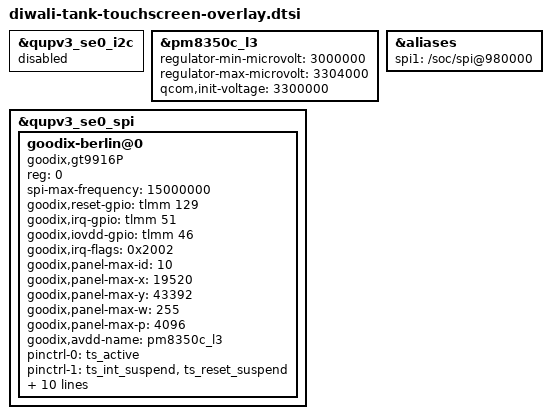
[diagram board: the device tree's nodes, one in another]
/*
 * Copyright (c) 2022, The Linux Foundation. All rights reserved.
 *
 * This program is free software; you can redistribute it and/or modify
 * it under the terms of the GNU General Public License version 2 and
 * only version 2 as published by the Free Software Foundation.
 *
 * This program is distributed in the hope that it will be useful,
 * but WITHOUT ANY WARRANTY; without even the implied warranty of
 * MERCHANTABILITY or FITNESS FOR A PARTICULAR PURPOSE.  See the
 * GNU General Public License for more details.
 */
#include <dt-bindings/clock/qcom,rpmh.h>

&qupv3_se0_i2c {
	status = "disabled";
};

&pm8350c_l3 {
	regulator-min-microvolt = <3000000>;
	regulator-max-microvolt = <3304000>;
	qcom,init-voltage = <3300000>;
};

&qupv3_se0_spi {
	#address-cells = <1>;
	#size-cells = <0>;

	status = "ok";

	goodix-berlin@0 {
		status = "ok";
		compatible = "goodix,gt9916P";
		reg = <0>;
		spi-max-frequency = <15000000>;

		goodix,reset-gpio = <&tlmm 129 0x0>;
		goodix,irq-gpio = <&tlmm 51 0x2002>;
		goodix,iovdd-gpio = <&tlmm 46 0x0>;
		goodix,irq-flags = <0x2002>; /* 1:trigger rising, 2:trigger falling;*/
		goodix,panel-max-id = <10>;
		goodix,panel-max-x = <19520>;
		goodix,panel-max-y = <43392>;
		goodix,panel-max-w = <255>;
		goodix,panel-max-p = <4096>;
		goodix,avdd-name = "pm8350c_l3";
		pinctrl-names = "pmx_ts_active", "pmx_ts_suspend", "pmx_ts_release";
		pinctrl-0 = <&ts_active>;
		pinctrl-1 = <&ts_int_suspend &ts_reset_suspend>;
		pinctrl-2 = <&ts_release>;

		mmi,power-off-suspend;
		mmi,usb-charger-detection;
		goodix,interpolation-ctrl;
		goodix,edge-ctrl;
		goodix,sample-ctrl;
		mmi,enable-gestures;
		mmi,supported_gesture_type = <0x06>;
		goodix,gesture-wait-pm;
		mmi,enable-palm;
	};
};

&aliases {
	spi1 = "/soc/spi@980000";
};
